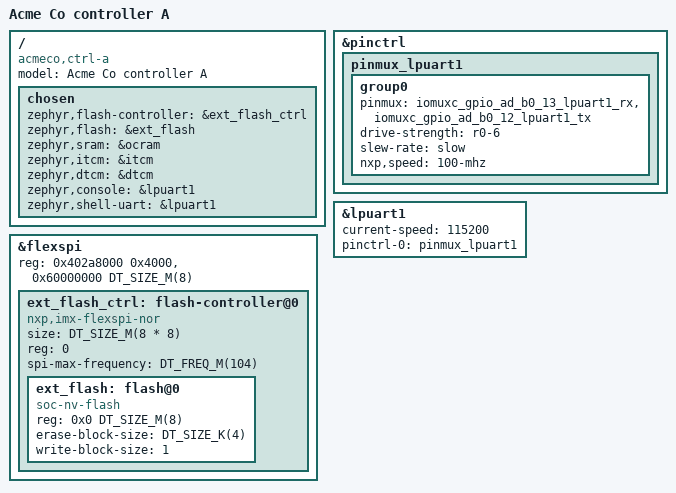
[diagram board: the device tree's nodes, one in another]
/*
 * SPDX-License-Identifier: Apache-2.0
 *
 * A fictional controller board with an i.MX RT1062, shared by two products.
 * Every value below is a placeholder until it is checked against the board's
 * schematic: console pins, flash part and size, and memory.
 */

/dts-v1/;

#include <nxp/imxrt/nxp_rt1060.dtsi>
#include <nxp/nxp_imx/rt/mimxrt1062dvl6a-pinctrl.dtsi>

/ {
	model = "Acme Co controller A";
	compatible = "acmeco,ctrl-a", "nxp,mimxrt1062";

	chosen {
		zephyr,flash-controller = &ext_flash_ctrl;
		zephyr,flash = &ext_flash;
		zephyr,sram = &ocram;
		zephyr,itcm = &itcm;
		zephyr,dtcm = &dtcm;
		zephyr,console = &lpuart1;
		zephyr,shell-uart = &lpuart1;
	};
};

&pinctrl {
	pinmux_lpuart1: pinmux_lpuart1 {
		group0 {
			pinmux = <&iomuxc_gpio_ad_b0_13_lpuart1_rx>,
				 <&iomuxc_gpio_ad_b0_12_lpuart1_tx>;
			drive-strength = "r0-6";
			slew-rate = "slow";
			nxp,speed = "100-mhz";
		};
	};
};

&lpuart1 {
	status = "okay";
	current-speed = <115200>;
	pinctrl-0 = <&pinmux_lpuart1>;
	pinctrl-names = "default";
};

&flexspi {
	status = "okay";
	reg = <0x402a8000 0x4000>, <0x60000000 DT_SIZE_M(8)>;

	ext_flash_ctrl: flash-controller@0 {
		compatible = "nxp,imx-flexspi-nor";
		size = <DT_SIZE_M(8 * 8)>;
		reg = <0>;
		spi-max-frequency = <DT_FREQ_M(104)>;
		status = "okay";
		#address-cells = <1>;
		#size-cells = <1>;
		ranges = <0x0 0x60000000 DT_SIZE_M(8)>;

		ext_flash: flash@0 {
			compatible = "soc-nv-flash";
			reg = <0x0 DT_SIZE_M(8)>;
			erase-block-size = <DT_SIZE_K(4)>;
			write-block-size = <1>;
		};
	};
};
